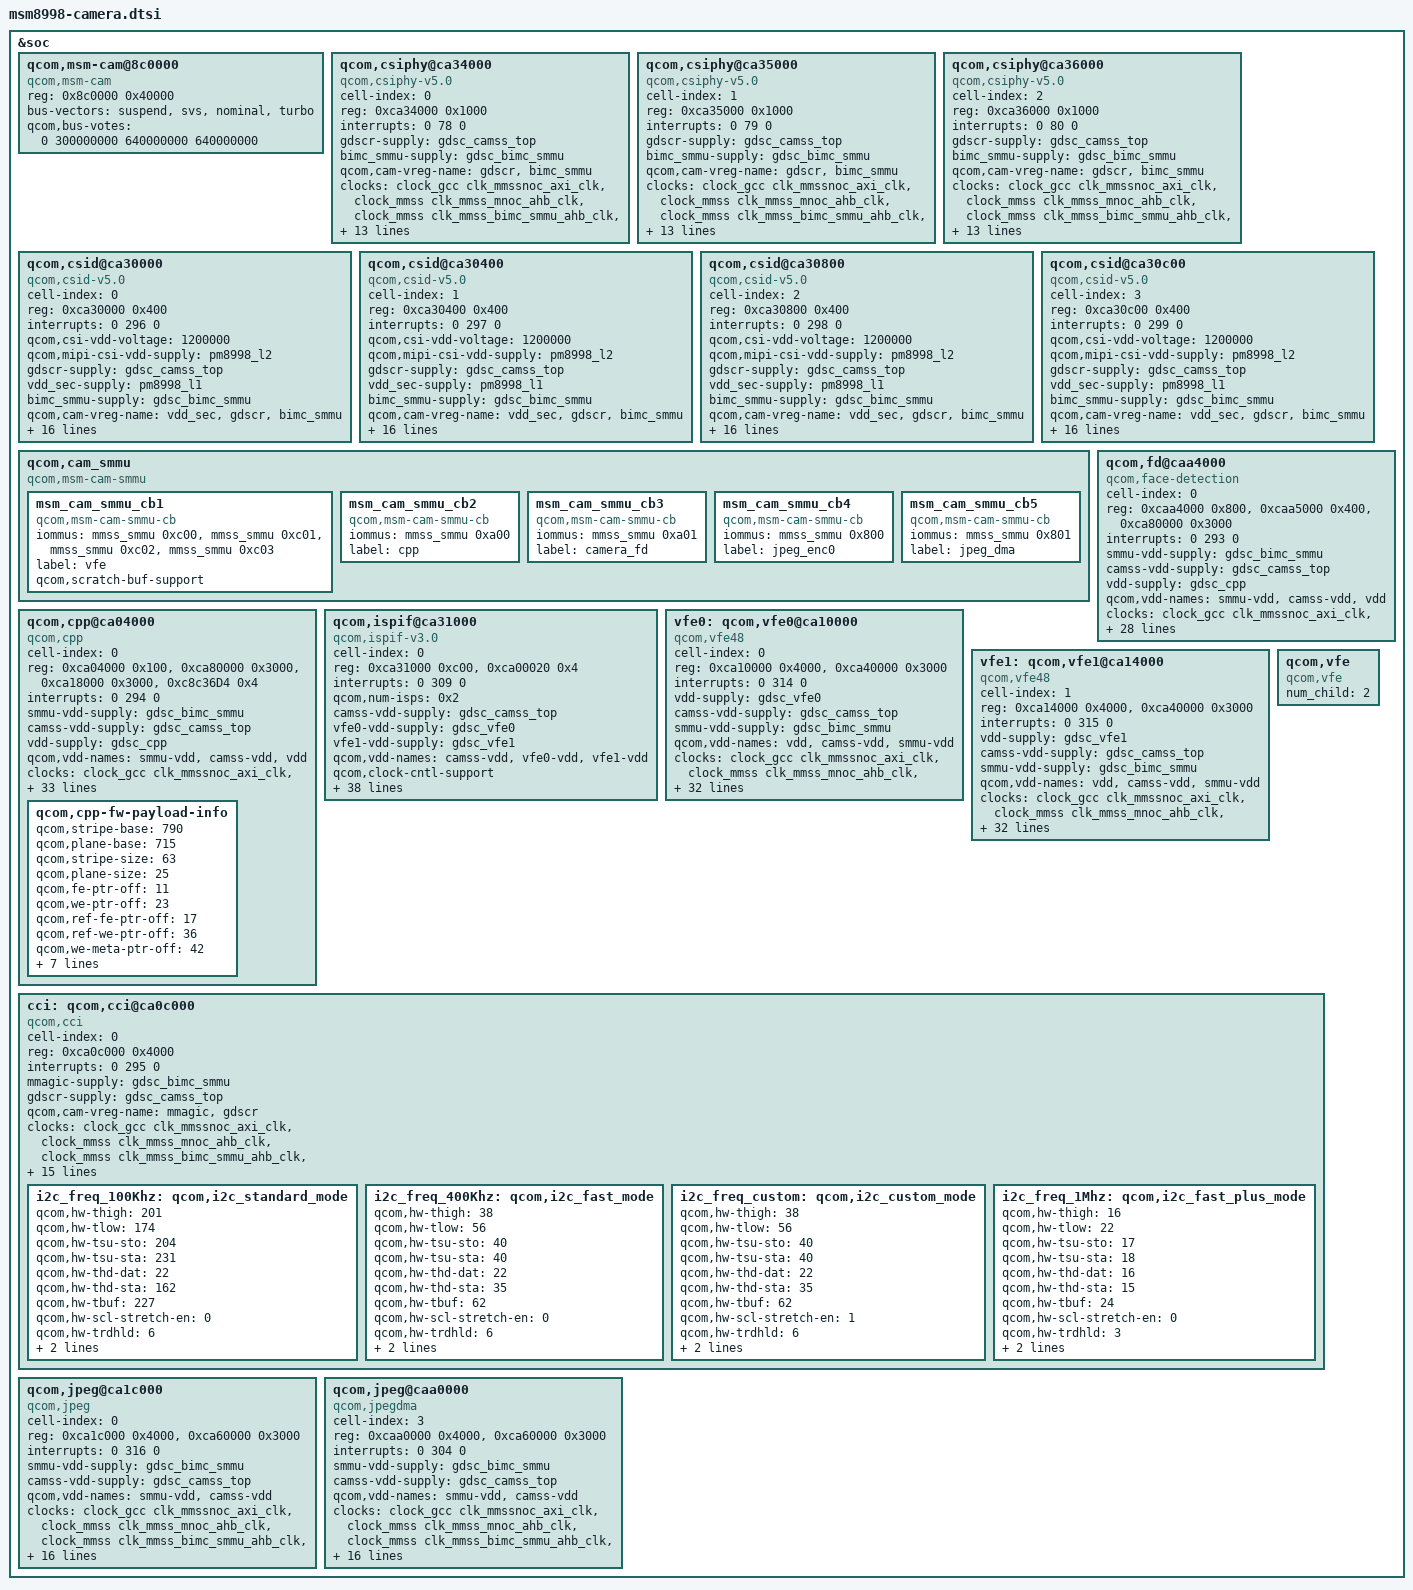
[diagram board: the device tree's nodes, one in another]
/*
 * Copyright (c) 2015-2017, The Linux Foundation. All rights reserved.
 *
 * This program is free software; you can redistribute it and/or modify
 * it under the terms of the GNU General Public License version 2 and
 * only version 2 as published by the Free Software Foundation.
 *
 * This program is distributed in the hope that it will be useful,
 * but WITHOUT ANY WARRANTY; without even the implied warranty of
 * MERCHANTABILITY or FITNESS FOR A PARTICULAR PURPOSE.  See the
 * GNU General Public License for more details.
 */

&soc {
	qcom,msm-cam@8c0000 {
		compatible = "qcom,msm-cam";
		reg = <0x8c0000 0x40000>;
		reg-names = "msm-cam";
		status = "ok";
		bus-vectors = "suspend", "svs", "nominal", "turbo";
		qcom,bus-votes = <0 300000000 640000000 640000000>;
	};

	qcom,csiphy@ca34000 {
		cell-index = <0>;
		compatible = "qcom,csiphy-v5.0", "qcom,csiphy";
		reg = <0xca34000 0x1000>;
		reg-names = "csiphy";
		interrupts = <0 78 0>;
		interrupt-names = "csiphy";
		gdscr-supply = <&gdsc_camss_top>;
		bimc_smmu-supply = <&gdsc_bimc_smmu>;
		qcom,cam-vreg-name = "gdscr", "bimc_smmu";
		clocks = <&clock_gcc clk_mmssnoc_axi_clk>,
			<&clock_mmss clk_mmss_mnoc_ahb_clk>,
			<&clock_mmss clk_mmss_bimc_smmu_ahb_clk>,
			<&clock_mmss clk_mmss_bimc_smmu_axi_clk>,
			<&clock_mmss clk_mmss_camss_ahb_clk>,
			<&clock_mmss clk_mmss_camss_top_ahb_clk>,
			<&clock_mmss clk_csi0_clk_src>,
			<&clock_mmss clk_mmss_camss_csi0_clk>,
			<&clock_mmss clk_mmss_camss_cphy_csid0_clk>,
			<&clock_mmss clk_csi0phytimer_clk_src>,
			<&clock_mmss clk_mmss_camss_csi0phytimer_clk>,
			<&clock_mmss clk_mmss_camss_ispif_ahb_clk>,
			<&clock_mmss clk_csiphy_clk_src>,
			<&clock_mmss clk_mmss_camss_csiphy0_clk>;
		clock-names = "mmssnoc_axi", "mnoc_ahb",
			"bmic_smmu_ahb", "bmic_smmu_axi",
			"camss_ahb_clk", "camss_top_ahb_clk",
			"csi_src_clk", "csi_clk", "cphy_csid_clk",
			"csiphy_timer_src_clk", "csiphy_timer_clk",
			"camss_ispif_ahb_clk", "csiphy_clk_src", "csiphy_clk";
		qcom,clock-rates = <0 0 0 0 0 0 274290000 0 0 200000000 0
			0 274290000 0>;
		status = "ok";
	};

	qcom,csiphy@ca35000 {
		cell-index = <1>;
		compatible = "qcom,csiphy-v5.0", "qcom,csiphy";
		reg = <0xca35000 0x1000>;
		reg-names = "csiphy";
		interrupts = <0 79 0>;
		interrupt-names = "csiphy";
		gdscr-supply = <&gdsc_camss_top>;
		bimc_smmu-supply = <&gdsc_bimc_smmu>;
		qcom,cam-vreg-name = "gdscr", "bimc_smmu";
		clocks = <&clock_gcc clk_mmssnoc_axi_clk>,
			<&clock_mmss clk_mmss_mnoc_ahb_clk>,
			<&clock_mmss clk_mmss_bimc_smmu_ahb_clk>,
			<&clock_mmss clk_mmss_bimc_smmu_axi_clk>,
			<&clock_mmss clk_mmss_camss_ahb_clk>,
			<&clock_mmss clk_mmss_camss_top_ahb_clk>,
			<&clock_mmss clk_csi1_clk_src>,
			<&clock_mmss clk_mmss_camss_csi1_clk>,
			<&clock_mmss clk_mmss_camss_cphy_csid1_clk>,
			<&clock_mmss clk_csi1phytimer_clk_src>,
			<&clock_mmss clk_mmss_camss_csi1phytimer_clk>,
			<&clock_mmss clk_mmss_camss_ispif_ahb_clk>,
			<&clock_mmss clk_csiphy_clk_src>,
			<&clock_mmss clk_mmss_camss_csiphy1_clk>;
		clock-names = "mmssnoc_axi", "mnoc_ahb",
			"bmic_smmu_ahb", "bmic_smmu_axi",
			"camss_ahb_clk", "camss_top_ahb_clk",
			"csi_src_clk", "csi_clk", "cphy_csid_clk",
			"csiphy_timer_src_clk", "csiphy_timer_clk",
			"camss_ispif_ahb_clk", "csiphy_clk_src", "csiphy_clk";
		qcom,clock-rates = <0 0 0 0 0 0 274290000 0 0 200000000 0
			0 274290000 0>;
		status = "ok";
	};

	qcom,csiphy@ca36000 {
		cell-index = <2>;
		compatible = "qcom,csiphy-v5.0", "qcom,csiphy";
		reg = <0xca36000 0x1000>;
		reg-names = "csiphy";
		interrupts = <0 80 0>;
		interrupt-names = "csiphy";
		gdscr-supply = <&gdsc_camss_top>;
		bimc_smmu-supply = <&gdsc_bimc_smmu>;
		qcom,cam-vreg-name = "gdscr", "bimc_smmu";
		clocks = <&clock_gcc clk_mmssnoc_axi_clk>,
			<&clock_mmss clk_mmss_mnoc_ahb_clk>,
			<&clock_mmss clk_mmss_bimc_smmu_ahb_clk>,
			<&clock_mmss clk_mmss_bimc_smmu_axi_clk>,
			<&clock_mmss clk_mmss_camss_ahb_clk>,
			<&clock_mmss clk_mmss_camss_top_ahb_clk>,
			<&clock_mmss clk_csi2_clk_src>,
			<&clock_mmss clk_mmss_camss_csi2_clk>,
			<&clock_mmss clk_mmss_camss_cphy_csid2_clk>,
			<&clock_mmss clk_csi2phytimer_clk_src>,
			<&clock_mmss clk_mmss_camss_csi2phytimer_clk>,
			<&clock_mmss clk_mmss_camss_ispif_ahb_clk>,
			<&clock_mmss clk_csiphy_clk_src>,
			<&clock_mmss clk_mmss_camss_csiphy2_clk>;
		clock-names = "mmssnoc_axi", "mnoc_ahb",
			"bmic_smmu_ahb", "bmic_smmu_axi",
			"camss_ahb_clk", "camss_top_ahb_clk",
			"csi_src_clk", "csi_clk", "cphy_csid_clk",
			"csiphy_timer_src_clk", "csiphy_timer_clk",
			"camss_ispif_ahb_clk", "csiphy_clk_src", "csiphy_clk";
		qcom,clock-rates = <0 0 0 0 0 0 274290000 0 0 200000000 0
			0 274290000 0>;
		status = "ok";
	};

	qcom,csid@ca30000  {
		cell-index = <0>;
		compatible = "qcom,csid-v5.0", "qcom,csid";
		reg = <0xca30000 0x400>;
		reg-names = "csid";
		interrupts = <0 296 0>;
		interrupt-names = "csid";
		qcom,csi-vdd-voltage = <1200000>;
		qcom,mipi-csi-vdd-supply = <&pm8998_l2>;
		gdscr-supply = <&gdsc_camss_top>;
		vdd_sec-supply = <&pm8998_l1>;
		bimc_smmu-supply = <&gdsc_bimc_smmu>;
		qcom,cam-vreg-name = "vdd_sec", "gdscr", "bimc_smmu";
		clocks = <&clock_gcc clk_mmssnoc_axi_clk>,
			<&clock_mmss clk_mmss_mnoc_ahb_clk>,
			<&clock_mmss clk_mmss_bimc_smmu_ahb_clk>,
			<&clock_mmss clk_mmss_bimc_smmu_axi_clk>,
			<&clock_mmss clk_mmss_camss_ahb_clk>,
			<&clock_mmss clk_mmss_camss_top_ahb_clk>,
			<&clock_mmss clk_mmss_camss_ispif_ahb_clk>,
			<&clock_mmss clk_csi0_clk_src>,
			<&clock_mmss clk_csiphy_clk_src>,
			<&clock_mmss clk_mmss_camss_csi0_clk>,
			<&clock_mmss clk_mmss_camss_csi0_ahb_clk>,
			<&clock_mmss clk_mmss_camss_csi0rdi_clk>,
			<&clock_mmss clk_mmss_camss_csi0pix_clk>,
			<&clock_mmss clk_mmss_camss_cphy_csid0_clk>;
		clock-names = "mmssnoc_axi", "mnoc_ahb",
			"bmic_smmu_ahb", "bmic_smmu_axi",
			"camss_ahb_clk", "camss_top_ahb_clk",
			"ispif_ahb_clk", "csi_src_clk", "csiphy_clk_src",
			"csi_clk", "csi_ahb_clk", "csi_rdi_clk",
			"csi_pix_clk", "cphy_csid_clk";
		qcom,clock-rates = <0 0 0 0 0 0 0 274290000 274290000
			0 0 0 0 0>;
		status = "ok";
	};

	qcom,csid@ca30400 {
		cell-index = <1>;
		compatible = "qcom,csid-v5.0", "qcom,csid";
		reg = <0xca30400 0x400>;
		reg-names = "csid";
		interrupts = <0 297 0>;
		interrupt-names = "csid";
		qcom,csi-vdd-voltage = <1200000>;
		qcom,mipi-csi-vdd-supply = <&pm8998_l2>;
		gdscr-supply = <&gdsc_camss_top>;
		vdd_sec-supply = <&pm8998_l1>;
		bimc_smmu-supply = <&gdsc_bimc_smmu>;
		qcom,cam-vreg-name = "vdd_sec", "gdscr", "bimc_smmu";
		clocks = <&clock_gcc clk_mmssnoc_axi_clk>,
			<&clock_mmss clk_mmss_mnoc_ahb_clk>,
			<&clock_mmss clk_mmss_bimc_smmu_ahb_clk>,
			<&clock_mmss clk_mmss_bimc_smmu_axi_clk>,
			<&clock_mmss clk_mmss_camss_ahb_clk>,
			<&clock_mmss clk_mmss_camss_top_ahb_clk>,
			<&clock_mmss clk_mmss_camss_ispif_ahb_clk>,
			<&clock_mmss clk_csi1_clk_src>,
			<&clock_mmss clk_csiphy_clk_src>,
			<&clock_mmss clk_mmss_camss_csi1_clk>,
			<&clock_mmss clk_mmss_camss_csi1_ahb_clk>,
			<&clock_mmss clk_mmss_camss_csi1rdi_clk>,
			<&clock_mmss clk_mmss_camss_csi1pix_clk>,
			<&clock_mmss clk_mmss_camss_cphy_csid1_clk>;
		clock-names = "mmssnoc_axi", "mnoc_ahb",
			"bmic_smmu_ahb", "bmic_smmu_axi",
			"camss_ahb_clk", "camss_top_ahb_clk",
			"ispif_ahb_clk", "csi_src_clk", "csiphy_clk_src",
			"csi_clk", "csi_ahb_clk", "csi_rdi_clk",
			"csi_pix_clk", "cphy_csid_clk";
		qcom,clock-rates = <0 0 0 0 0 0 0 274290000 274290000
			 0 0 0 0 0>;
		status = "ok";
	};

	qcom,csid@ca30800 {
		cell-index = <2>;
		compatible = "qcom,csid-v5.0", "qcom,csid";
		reg = <0xca30800 0x400>;
		reg-names = "csid";
		interrupts = <0 298 0>;
		interrupt-names = "csid";
		qcom,csi-vdd-voltage = <1200000>;
		qcom,mipi-csi-vdd-supply = <&pm8998_l2>;
		gdscr-supply = <&gdsc_camss_top>;
		vdd_sec-supply = <&pm8998_l1>;
		bimc_smmu-supply = <&gdsc_bimc_smmu>;
		qcom,cam-vreg-name = "vdd_sec", "gdscr", "bimc_smmu";
		clocks = <&clock_gcc clk_mmssnoc_axi_clk>,
			<&clock_mmss clk_mmss_mnoc_ahb_clk>,
			<&clock_mmss clk_mmss_bimc_smmu_ahb_clk>,
			<&clock_mmss clk_mmss_bimc_smmu_axi_clk>,
			<&clock_mmss clk_mmss_camss_ahb_clk>,
			<&clock_mmss clk_mmss_camss_top_ahb_clk>,
			<&clock_mmss clk_mmss_camss_ispif_ahb_clk>,
			<&clock_mmss clk_csi2_clk_src>,
			<&clock_mmss clk_csiphy_clk_src>,
			<&clock_mmss clk_mmss_camss_csi2_clk>,
			<&clock_mmss clk_mmss_camss_csi2_ahb_clk>,
			<&clock_mmss clk_mmss_camss_csi2rdi_clk>,
			<&clock_mmss clk_mmss_camss_csi2pix_clk>,
			<&clock_mmss clk_mmss_camss_cphy_csid2_clk>;
		clock-names = "mmssnoc_axi", "mnoc_ahb",
			"bmic_smmu_ahb", "bmic_smmu_axi",
			"camss_ahb_clk", "camss_top_ahb_clk",
			"ispif_ahb_clk", "csi_src_clk", "csiphy_clk_src",
			"csi_clk", "csi_ahb_clk", "csi_rdi_clk",
			"csi_pix_clk", "cphy_csid_clk";
		qcom,clock-rates = <0 0 0 0 0 0 0 274290000 274290000
			 0 0 0 0 0>;
		status = "ok";
	};

	qcom,csid@ca30c00 {
		cell-index = <3>;
		compatible = "qcom,csid-v5.0", "qcom,csid";
		reg = <0xca30c00 0x400>;
		reg-names = "csid";
		interrupts = <0 299 0>;
		interrupt-names = "csid";
		qcom,csi-vdd-voltage = <1200000>;
		qcom,mipi-csi-vdd-supply = <&pm8998_l2>;
		gdscr-supply = <&gdsc_camss_top>;
		vdd_sec-supply = <&pm8998_l1>;
		bimc_smmu-supply = <&gdsc_bimc_smmu>;
		qcom,cam-vreg-name = "vdd_sec", "gdscr", "bimc_smmu";
		clocks = <&clock_gcc clk_mmssnoc_axi_clk>,
			<&clock_mmss clk_mmss_mnoc_ahb_clk>,
			<&clock_mmss clk_mmss_bimc_smmu_ahb_clk>,
			<&clock_mmss clk_mmss_bimc_smmu_axi_clk>,
			<&clock_mmss clk_mmss_camss_ahb_clk>,
			<&clock_mmss clk_mmss_camss_top_ahb_clk>,
			<&clock_mmss clk_mmss_camss_ispif_ahb_clk>,
			<&clock_mmss clk_csi3_clk_src>,
			<&clock_mmss clk_csiphy_clk_src>,
			<&clock_mmss clk_mmss_camss_csi3_clk>,
			<&clock_mmss clk_mmss_camss_csi3_ahb_clk>,
			<&clock_mmss clk_mmss_camss_csi3rdi_clk>,
			<&clock_mmss clk_mmss_camss_csi3pix_clk>,
			<&clock_mmss clk_mmss_camss_cphy_csid3_clk>;
		clock-names = "mmssnoc_axi", "mnoc_ahb",
			"bmic_smmu_ahb", "bmic_smmu_axi",
			"camss_ahb_clk", "camss_top_ahb_clk",
			"ispif_ahb_clk", "csi_src_clk", "csiphy_clk_src",
			"csi_clk", "csi_ahb_clk", "csi_rdi_clk",
			"csi_pix_clk", "cphy_csid_clk";
		qcom,clock-rates = <0 0 0 0 0 0 0 274290000 274290000
			 0 0 0 0 0>;
		status = "ok";
	};

	qcom,cam_smmu {
		compatible = "qcom,msm-cam-smmu";
		status = "ok";

		msm_cam_smmu_cb1 {
			compatible = "qcom,msm-cam-smmu-cb";
			iommus = <&mmss_smmu 0xc00>,
					<&mmss_smmu 0xc01>,
					<&mmss_smmu 0xc02>,
					<&mmss_smmu 0xc03>;
			label = "vfe";
			qcom,scratch-buf-support;
		};

		msm_cam_smmu_cb2 {
			compatible = "qcom,msm-cam-smmu-cb";
			iommus = <&mmss_smmu 0xa00>;
			label = "cpp";
		};

		msm_cam_smmu_cb3 {
			compatible = "qcom,msm-cam-smmu-cb";
			iommus = <&mmss_smmu 0xa01>;
			label = "camera_fd";
		};

		msm_cam_smmu_cb4 {
			compatible = "qcom,msm-cam-smmu-cb";
			iommus = <&mmss_smmu 0x800>;
			label = "jpeg_enc0";
		};

		msm_cam_smmu_cb5 {
			compatible = "qcom,msm-cam-smmu-cb";
			iommus = <&mmss_smmu 0x801>;
			label = "jpeg_dma";
		};
	};

	qcom,fd@caa4000 {
		cell-index = <0>;
		compatible = "qcom,face-detection";
		reg = <0xcaa4000 0x800>,
			<0xcaa5000 0x400>,
			<0xca80000 0x3000>;
		reg-names = "fd_core", "fd_misc", "fd_vbif";
		interrupts = <0 293 0>;
		interrupt-names = "fd";
		smmu-vdd-supply = <&gdsc_bimc_smmu>;
		camss-vdd-supply = <&gdsc_camss_top>;
		vdd-supply = <&gdsc_cpp>;
		qcom,vdd-names = "smmu-vdd", "camss-vdd", "vdd";
		clocks = <&clock_gcc clk_mmssnoc_axi_clk>,
			<&clock_mmss clk_mmss_mnoc_ahb_clk>,
			<&clock_mmss clk_mmss_bimc_smmu_ahb_clk>,
			<&clock_mmss clk_mmss_bimc_smmu_axi_clk>,
			<&clock_mmss clk_mmss_camss_ahb_clk>,
			<&clock_mmss clk_mmss_camss_top_ahb_clk>,
			<&clock_mmss clk_mmss_fd_core_clk>,
			<&clock_mmss clk_mmss_fd_core_uar_clk>,
			<&clock_mmss clk_mmss_fd_ahb_clk>,
			<&clock_mmss clk_mmss_camss_cpp_axi_clk>,
			<&clock_mmss clk_mmss_camss_cpp_vbif_ahb_clk>;
		clock-names = "mmssnoc_axi",
			"mmss_mnoc_ahb_clk",
			"mmss_bimc_smmu_ahb_clk",
			"mmss_bimc_smmu_axi_clk",
			"mmss_camss_ahb_clk",
			"mmss_camss_top_ahb_clk",
			"mmss_fd_core_clk",
			"mmss_fd_core_uar_clk",
			"mmss_fd_ahb_clk",
			"mmss_camss_cpp_axi_clk",
			"mmss_camss_cpp_vbif_ahb_clk";
		qcom,clock-rates =
			<0 0 0 0 0 0 404000000 0 0 0 0>,
			<0 0 0 0 0 0 100000000 0 0 0 0>,
			<0 0 0 0 0 0 404000000 0 0 0 0>,
			<0 0 0 0 0 0 404000000 0 0 0 0>;
		qcom,msm-bus,name = "msm_camera_fd";
		qcom,msm-bus,num-cases = <4>;
		qcom,msm-bus,num-paths = <1>;
		qcom,msm-bus,vectors-KBps = <106 512 0 0>,
			<106 512 1625 0>,
			<106 512 2995 0>,
			<106 512 7200 0>;
		qcom,fd-vbif-reg-settings = <0x20 0x10000000 0x30000000>,
			<0x24 0x10000000 0x30000000>,
			<0x28 0x10000000 0x30000000>,
			<0x2c 0x10000000 0x30000000>;
		qcom,fd-misc-reg-settings = <0x20 0x2 0x3>,
			<0x24 0x2 0x3>;
		status = "ok";
	};

	qcom,cpp@ca04000 {
		cell-index = <0>;
		compatible = "qcom,cpp";
		reg = <0xca04000 0x100>,
			<0xca80000 0x3000>,
			<0xca18000 0x3000>,
			<0xc8c36D4 0x4>;
		reg-names = "cpp", "cpp_vbif", "cpp_hw", "camss_cpp";
		interrupts = <0 294 0>;
		interrupt-names = "cpp";
		smmu-vdd-supply = <&gdsc_bimc_smmu>;
		camss-vdd-supply = <&gdsc_camss_top>;
		vdd-supply = <&gdsc_cpp>;
		qcom,vdd-names = "smmu-vdd", "camss-vdd", "vdd";
		clocks = <&clock_gcc clk_mmssnoc_axi_clk>,
			<&clock_mmss clk_mmss_mnoc_ahb_clk>,
			<&clock_mmss clk_mmss_camss_ahb_clk>,
			<&clock_mmss clk_mmss_camss_top_ahb_clk>,
			<&clock_mmss clk_cpp_clk_src>,
			<&clock_mmss clk_mmss_camss_cpp_clk>,
			<&clock_mmss clk_mmss_camss_cpp_ahb_clk>,
			<&clock_mmss clk_mmss_camss_cpp_axi_clk>,
			<&clock_mmss clk_mmss_camss_micro_ahb_clk>,
			<&clock_mmss clk_mmss_bimc_smmu_axi_clk>,
			<&clock_mmss clk_mmss_camss_cpp_vbif_ahb_clk>;
		clock-names = "mmssnoc_axi_clk",
			"mnoc_ahb_clk",
			"camss_ahb_clk", "camss_top_ahb_clk",
			"cpp_src_clk",
			"cpp_core_clk", "camss_cpp_ahb_clk",
			"camss_cpp_axi_clk", "micro_iface_clk",
			"mmss_smmu_axi_clk", "cpp_vbif_ahb_clk";
		qcom,clock-rates = <0 0 0 0 200000000 200000000 0 0 0 0 0>;
		qcom,min-clock-rate = <200000000>;
		qcom,bus-master = <1>;
		qcom,vbif-qos-setting = <0x550 0x33333333>,
			<0x554 0x03333333>,
			<0x558 0x33333333>,
			<0x55c 0x03333333>,
			<0x560 0x33333333>,
			<0x564 0x03333333>,
			<0x568 0x33333333>,
			<0x56c 0x03333333>,
			<0x570 0x33333333>,
			<0x574 0x03333333>,
			<0x578 0x33333333>,
			<0x57c 0x03333333>,
			<0x580 0x33333333>,
			<0x584 0x03333333>,
			<0x588 0x33333333>,
			<0x58c 0x03333333>;
		status = "ok";
		qcom,msm-bus,name = "msm_camera_cpp";
		qcom,msm-bus,num-cases = <2>;
		qcom,msm-bus,num-paths = <1>;
		qcom,msm-bus,vectors-KBps =
			<106 512 0 0>,
			<106 512 0 0>;
		qcom,msm-bus-vector-dyn-vote;
		resets = <&clock_mmss CAMSS_MICRO_BCR>;
		reset-names = "micro_iface_reset";
		qcom,src-clock-rates = <100000000 200000000 576000000
			600000000>;
		qcom,micro-reset;
		qcom,cpp-fw-payload-info {
			qcom,stripe-base = <790>;
			qcom,plane-base = <715>;
			qcom,stripe-size = <63>;
			qcom,plane-size = <25>;
			qcom,fe-ptr-off = <11>;
			qcom,we-ptr-off = <23>;
			qcom,ref-fe-ptr-off = <17>;
			qcom,ref-we-ptr-off = <36>;
			qcom,we-meta-ptr-off = <42>;
			qcom,fe-mmu-pf-ptr-off = <7>;
			qcom,ref-fe-mmu-pf-ptr-off = <10>;
			qcom,we-mmu-pf-ptr-off = <13>;
			qcom,dup-we-mmu-pf-ptr-off = <18>;
			qcom,ref-we-mmu-pf-ptr-off = <23>;
			qcom,set-group-buffer-len = <135>;
			qcom,dup-frame-indicator-off = <70>;
		};
	};

	qcom,ispif@ca31000 {
		cell-index = <0>;
		compatible = "qcom,ispif-v3.0", "qcom,ispif";
		reg = <0xca31000 0xc00>,
			<0xca00020 0x4>;
		reg-names = "ispif", "csi_clk_mux";
		interrupts = <0 309 0>;
		interrupt-names = "ispif";
		qcom,num-isps = <0x2>;
		camss-vdd-supply = <&gdsc_camss_top>;
		vfe0-vdd-supply = <&gdsc_vfe0>;
		vfe1-vdd-supply = <&gdsc_vfe1>;
		qcom,vdd-names = "camss-vdd", "vfe0-vdd",
				"vfe1-vdd";
		qcom,clock-cntl-support;
		clocks = <&clock_gcc clk_mmssnoc_axi_clk>,
			<&clock_mmss clk_mmss_mnoc_ahb_clk>,
			<&clock_mmss clk_mmss_camss_ahb_clk>,
			<&clock_mmss clk_mmss_camss_top_ahb_clk>,
			<&clock_mmss clk_mmss_camss_ispif_ahb_clk>,
			<&clock_mmss clk_csi0_clk_src>,
			<&clock_mmss clk_csi1_clk_src>,
			<&clock_mmss clk_csi2_clk_src>,
			<&clock_mmss clk_csi3_clk_src>,
			<&clock_mmss clk_mmss_camss_csi0rdi_clk>,
			<&clock_mmss clk_mmss_camss_csi1rdi_clk>,
			<&clock_mmss clk_mmss_camss_csi2rdi_clk>,
			<&clock_mmss clk_mmss_camss_csi3rdi_clk>,
			<&clock_mmss clk_mmss_camss_csi0pix_clk>,
			<&clock_mmss clk_mmss_camss_csi1pix_clk>,
			<&clock_mmss clk_mmss_camss_csi2pix_clk>,
			<&clock_mmss clk_mmss_camss_csi3pix_clk>,
			<&clock_mmss clk_mmss_camss_csi0_clk>,
			<&clock_mmss clk_mmss_camss_csi1_clk>,
			<&clock_mmss clk_mmss_camss_csi2_clk>,
			<&clock_mmss clk_mmss_camss_csi3_clk>,
			<&clock_mmss clk_vfe0_clk_src>,
			<&clock_mmss clk_mmss_camss_vfe0_clk>,
			<&clock_mmss clk_mmss_camss_csi_vfe0_clk>,
			<&clock_mmss clk_vfe1_clk_src>,
			<&clock_mmss clk_mmss_camss_vfe1_clk>,
			<&clock_mmss clk_mmss_camss_csi_vfe1_clk>;
		clock-names = "mmssnoc_axi", "mnoc_ahb_clk",
			"camss_ahb_clk",
			"camss_top_ahb_clk", "ispif_ahb_clk",
			"csi0_src_clk", "csi1_src_clk",
			"csi2_src_clk", "csi3_src_clk",
			"csi0_rdi_clk", "csi1_rdi_clk",
			"csi2_rdi_clk", "csi3_rdi_clk",
			"csi0_pix_clk", "csi1_pix_clk",
			"csi2_pix_clk", "csi3_pix_clk",
			"camss_csi0_clk", "camss_csi1_clk",
			"camss_csi2_clk", "camss_csi3_clk",
			"vfe0_clk_src",
			"camss_vfe_vfe0_clk",
			"camss_csi_vfe0_clk",
			"vfe1_clk_src",
			"camss_vfe_vfe1_clk",
			"camss_csi_vfe1_clk";
		qcom,clock-rates = <0 0 0 0 0
			0 0 0 0
			0 0 0 0
			0 0 0 0
			0 0 0 0
			0 0 0
			0 0 0>;
		qcom,clock-control = "INIT_RATE", "NO_SET_RATE",
			"NO_SET_RATE", "NO_SET_RATE",
			"NO_SET_RATE",
			"INIT_RATE", "INIT_RATE",
			"INIT_RATE", "INIT_RATE",
			"NO_SET_RATE", "NO_SET_RATE",
			"NO_SET_RATE", "NO_SET_RATE",
			"NO_SET_RATE", "NO_SET_RATE",
			"NO_SET_RATE", "NO_SET_RATE",
			"NO_SET_RATE", "NO_SET_RATE",
			"NO_SET_RATE", "NO_SET_RATE",
			"INIT_RATE",
			"NO_SET_RATE", "NO_SET_RATE",
			"INIT_RATE",
			"NO_SET_RATE", "NO_SET_RATE";
		status = "ok";
	};

	vfe0: qcom,vfe0@ca10000 {
		cell-index = <0>;
		compatible = "qcom,vfe48";
		reg = <0xca10000 0x4000>,
			<0xca40000 0x3000>;
		reg-names = "vfe", "vfe_vbif";
		interrupts = <0 314 0>;
		interrupt-names = "vfe";
		vdd-supply = <&gdsc_vfe0>;
		camss-vdd-supply = <&gdsc_camss_top>;
		smmu-vdd-supply = <&gdsc_bimc_smmu>;
		qcom,vdd-names = "vdd", "camss-vdd", "smmu-vdd";
		clocks = <&clock_gcc clk_mmssnoc_axi_clk>,
			<&clock_mmss clk_mmss_mnoc_ahb_clk>,
			<&clock_mmss clk_mmss_bimc_smmu_ahb_clk>,
			<&clock_mmss clk_mmss_bimc_smmu_axi_clk>,
			<&clock_mmss clk_mmss_camss_ahb_clk>,
			<&clock_mmss clk_mmss_camss_top_ahb_clk>,
			<&clock_mmss clk_vfe0_clk_src>,
			<&clock_mmss clk_mmss_camss_vfe0_clk>,
			<&clock_mmss clk_mmss_camss_vfe0_stream_clk>,
			<&clock_mmss clk_mmss_camss_vfe0_ahb_clk>,
			<&clock_mmss clk_mmss_camss_vfe_vbif_ahb_clk>,
			<&clock_mmss clk_mmss_camss_vfe_vbif_axi_clk>,
			<&clock_mmss clk_mmss_camss_csi_vfe0_clk>;
		clock-names = "mmssnoc_axi", "mnoc_ahb_clk",
			"bimc_smmu_ahb_clk", "bimc_smmu_axi_clk",
			"camss_ahb_clk", "camss_top_ahb_clk", "vfe_clk_src",
			"camss_vfe_clk", "camss_vfe_stream_clk",
			"camss_vfe_ahb_clk", "camss_vfe_vbif_ahb_clk",
			"camss_vfe_vbif_axi_clk",
			"camss_csi_vfe_clk";
		qcom,clock-rates = <0 0 0 0 0 0 480000000 0 0 0 0 0 0
					0 0 0 0 0 0 576000000 0 0 0 0 0 0
					0 0 0 0 0 0 600000000 0 0 0 0 0 0>;
		status = "ok";
		qos-entries = <8>;
		qos-regs = <0x404 0x408 0x40c 0x410 0x414 0x418
			0x41c 0x420>;
		qos-settings = <0xaaa9aaa9
			0xaaa9aaa9
			0xaaa9aaa9
			0xaaa9aaa9
			0xaaa9aaa9
			0xaaa9aaa9
			0xaaa9aaa9
			0xaaa9aaa9>;
		vbif-entries = <1>;
		vbif-regs = <0x124>;
		vbif-settings = <0x3>;
		ds-entries = <17>;
		ds-regs = <0x424 0x428 0x42c 0x430 0x434
			0x438 0x43c 0x440 0x444 0x448 0x44c
			0x450 0x454 0x458 0x45c 0x460 0x464>;
		ds-settings = <0xcccc0011
			0xcccc0011
			0xcccc0011
			0xcccc0011
			0xcccc0011
			0xcccc0011
			0xcccc0011
			0xcccc0011
			0xcccc0011
			0xcccc0011
			0xcccc0011
			0xcccc0011
			0xcccc0011
			0xcccc0011
			0xcccc0011
			0xcccc0011
			0x40000103>;
		qcom,msm-bus,name = "msm_camera_vfe";
		qcom,msm-bus,num-cases = <2>;
		qcom,msm-bus,num-paths = <1>;
		qcom,msm-bus,vectors-KBps =
			<29 512 0 0>,
			<29 512 100000000 100000000>;
		qcom,msm-bus-vector-dyn-vote;
	};

	vfe1: qcom,vfe1@ca14000 {
		cell-index = <1>;
		compatible = "qcom,vfe48";
		reg = <0xca14000 0x4000>,
			<0xca40000 0x3000>;
		reg-names = "vfe", "vfe_vbif";
		interrupts = <0 315 0>;
		interrupt-names = "vfe";
		vdd-supply = <&gdsc_vfe1>;
		camss-vdd-supply = <&gdsc_camss_top>;
		smmu-vdd-supply = <&gdsc_bimc_smmu>;
		qcom,vdd-names = "vdd", "camss-vdd", "smmu-vdd";
		clocks = <&clock_gcc clk_mmssnoc_axi_clk>,
			<&clock_mmss clk_mmss_mnoc_ahb_clk>,
			<&clock_mmss clk_mmss_bimc_smmu_ahb_clk>,
			<&clock_mmss clk_mmss_bimc_smmu_axi_clk>,
			<&clock_mmss clk_mmss_camss_ahb_clk>,
			<&clock_mmss clk_mmss_camss_top_ahb_clk>,
			<&clock_mmss clk_vfe1_clk_src>,
			<&clock_mmss clk_mmss_camss_vfe1_clk>,
			<&clock_mmss clk_mmss_camss_vfe1_stream_clk>,
			<&clock_mmss clk_mmss_camss_vfe1_ahb_clk>,
			<&clock_mmss clk_mmss_camss_vfe_vbif_ahb_clk>,
			<&clock_mmss clk_mmss_camss_vfe_vbif_axi_clk>,
			<&clock_mmss clk_mmss_camss_csi_vfe1_clk>;
		clock-names = "mmssnoc_axi", "mnoc_ahb_clk",
			"bimc_smmu_ahb_clk", "bimc_smmu_axi_clk",
			"camss_ahb_clk", "camss_top_ahb_clk", "vfe_clk_src",
			"camss_vfe_clk", "camss_vfe_stream_clk",
			"camss_vfe_ahb_clk", "camss_vfe_vbif_ahb_clk",
			"camss_vfe_vbif_axi_clk",
			"camss_csi_vfe_clk";
		qcom,clock-rates = <0 0 0 0 0 0 480000000 0 0 0 0 0 0
					0 0 0 0 0 0 576000000 0 0 0 0 0 0
					0 0 0 0 0 0 600000000 0 0 0 0 0 0>;
		status = "ok";
		qos-entries = <8>;
		qos-regs = <0x404 0x408 0x40c 0x410 0x414 0x418
			0x41c 0x420>;
		qos-settings = <0xaaa9aaa9
			0xaaa9aaa9
			0xaaa9aaa9
			0xaaa9aaa9
			0xaaa9aaa9
			0xaaa9aaa9
			0xaaa9aaa9
			0xaaa9aaa9>;
		vbif-entries = <1>;
		vbif-regs = <0x124>;
		vbif-settings = <0x3>;
		ds-entries = <17>;
		ds-regs = <0x424 0x428 0x42c 0x430 0x434
			0x438 0x43c 0x440 0x444 0x448 0x44c
			0x450 0x454 0x458 0x45c 0x460 0x464>;
		ds-settings = <0xcccc0011
			0xcccc0011
			0xcccc0011
			0xcccc0011
			0xcccc0011
			0xcccc0011
			0xcccc0011
			0xcccc0011
			0xcccc0011
			0xcccc0011
			0xcccc0011
			0xcccc0011
			0xcccc0011
			0xcccc0011
			0xcccc0011
			0xcccc0011
			0x40000103>;
		qcom,msm-bus,name = "msm_camera_vfe";
		qcom,msm-bus,num-cases = <2>;
		qcom,msm-bus,num-paths = <1>;
		qcom,msm-bus,vectors-KBps =
			<29 512 0 0>,
			<29 512 100000000 100000000>;
		qcom,msm-bus-vector-dyn-vote;
	};

	qcom,vfe {
		compatible = "qcom,vfe";
		num_child = <2>;
	};

	cci: qcom,cci@ca0c000 {
		cell-index = <0>;
		compatible = "qcom,cci";
		reg = <0xca0c000 0x4000>;
		#address-cells = <1>;
		#size-cells = <0>;
		reg-names = "cci";
		interrupts = <0 295 0>;
		interrupt-names = "cci";
		status = "ok";
		mmagic-supply = <&gdsc_bimc_smmu>;
		gdscr-supply = <&gdsc_camss_top>;
		qcom,cam-vreg-name = "mmagic", "gdscr";
		clocks = <&clock_gcc clk_mmssnoc_axi_clk>,
			<&clock_mmss clk_mmss_mnoc_ahb_clk>,
			<&clock_mmss clk_mmss_bimc_smmu_ahb_clk>,
			<&clock_mmss clk_mmss_bimc_smmu_axi_clk>,
			<&clock_mmss clk_mmss_camss_ahb_clk>,
			<&clock_mmss clk_mmss_camss_top_ahb_clk>,
			<&clock_mmss clk_cci_clk_src>,
			<&clock_mmss clk_mmss_camss_cci_ahb_clk>,
			<&clock_mmss clk_mmss_camss_cci_clk>;
		clock-names = "mmssnoc_axi", "mnoc_ahb", "smmu_ahb", "smmu_axi",
			"camss_ahb_clk", "camss_top_ahb_clk",
			"cci_src_clk", "cci_ahb_clk", "camss_cci_clk";
		qcom,clock-rates = <0 0 0 0 0 0 19200000 0 0>,
			<0 0 0 0 0 0 37500000 0 0>;
		pinctrl-names = "cci_default", "cci_suspend";
			pinctrl-0 = <&cci0_active &cci1_active>;
			pinctrl-1 = <&cci0_suspend &cci1_suspend>;
		gpios = <&tlmm 17 0>,
			<&tlmm 18 0>,
			<&tlmm 19 0>,
			<&tlmm 20 0>;
		qcom,gpio-tbl-num = <0 1 2 3>;
		qcom,gpio-tbl-flags = <1 1 1 1>;
		qcom,gpio-tbl-label = "CCI_I2C_DATA0",
				      "CCI_I2C_CLK0",
				      "CCI_I2C_DATA1",
				      "CCI_I2C_CLK1";
		i2c_freq_100Khz: qcom,i2c_standard_mode {
			status = "disabled";
		};
		i2c_freq_400Khz: qcom,i2c_fast_mode {
			status = "disabled";
		};
		i2c_freq_custom: qcom,i2c_custom_mode {
			status = "disabled";
		};
		i2c_freq_1Mhz: qcom,i2c_fast_plus_mode {
			status = "disabled";
		};
	};

	qcom,jpeg@ca1c000 {
		cell-index = <0>;
		compatible = "qcom,jpeg";
		reg = <0xca1c000 0x4000>,
			<0xca60000 0x3000>;
		reg-names = "jpeg_hw", "jpeg_vbif";
		interrupts = <0 316 0>;
		interrupt-names = "jpeg";
		smmu-vdd-supply = <&gdsc_bimc_smmu>;
		camss-vdd-supply = <&gdsc_camss_top>;
		qcom,vdd-names = "smmu-vdd", "camss-vdd";
		clock-names = "mmssnoc_axi",
			"mmss_mnoc_ahb_clk",
			"mmss_bimc_smmu_ahb_clk",
			"mmss_bimc_smmu_axi_clk",
			"mmss_camss_ahb_clk",
			"mmss_camss_top_ahb_clk",
			"core_clk",
			"mmss_camss_jpeg_ahb_clk",
			"mmss_camss_jpeg_axi_clk";
		clocks = <&clock_gcc clk_mmssnoc_axi_clk>,
			<&clock_mmss clk_mmss_mnoc_ahb_clk>,
			<&clock_mmss clk_mmss_bimc_smmu_ahb_clk>,
			<&clock_mmss clk_mmss_bimc_smmu_axi_clk>,
			<&clock_mmss clk_mmss_camss_ahb_clk>,
			<&clock_mmss clk_mmss_camss_top_ahb_clk>,
			<&clock_mmss clk_mmss_camss_jpeg0_vote_clk>,
			<&clock_mmss clk_mmss_camss_jpeg_ahb_clk>,
			<&clock_mmss clk_mmss_camss_jpeg_axi_clk>;
		qcom,clock-rates = <0 0 0 0 0 0 480000000 0 0>;
		qcom,vbif-reg-settings = <0x4 0x1>;
		qcom,prefetch-reg-settings = <0x30c 0x1111>,
			<0x318 0x31>,
			<0x324 0x31>,
			<0x330 0x31>,
			<0x33c 0x0>;
		qcom,msm-bus,name = "msm_camera_jpeg0";
		qcom,msm-bus,num-cases = <2>;
		qcom,msm-bus,num-paths = <1>;
		qcom,msm-bus,vectors-KBps = <62 512 0 0>,
			<62 512 1920000 2880000>;
		status = "ok";
	};

	qcom,jpeg@caa0000 {
		cell-index = <3>;
		compatible = "qcom,jpegdma";
		reg = <0xcaa0000 0x4000>,
			<0xca60000 0x3000>;
		reg-names = "jpeg_hw", "jpeg_vbif";
		interrupts = <0 304 0>;
		interrupt-names = "jpeg";
		smmu-vdd-supply = <&gdsc_bimc_smmu>;
		camss-vdd-supply = <&gdsc_camss_top>;
		qcom,vdd-names = "smmu-vdd", "camss-vdd";
		clock-names = "mmssnoc_axi",
			"mmss_mnoc_ahb_clk",
			"mmss_bimc_smmu_ahb_clk",
			"mmss_bimc_smmu_axi_clk",
			"mmss_camss_ahb_clk",
			"mmss_camss_top_ahb_clk",
			"core_clk",
			"mmss_camss_jpeg_ahb_clk",
			"mmss_camss_jpeg_axi_clk";
		clocks = <&clock_gcc clk_mmssnoc_axi_clk>,
			<&clock_mmss clk_mmss_mnoc_ahb_clk>,
			<&clock_mmss clk_mmss_bimc_smmu_ahb_clk>,
			<&clock_mmss clk_mmss_bimc_smmu_axi_clk>,
			<&clock_mmss clk_mmss_camss_ahb_clk>,
			<&clock_mmss clk_mmss_camss_top_ahb_clk>,
			<&clock_mmss clk_mmss_camss_jpeg0_dma_vote_clk>,
			<&clock_mmss clk_mmss_camss_jpeg_ahb_clk>,
			<&clock_mmss clk_mmss_camss_jpeg_axi_clk>;
		qcom,clock-rates = <0 0 0 0 0 0 480000000 0 0>;
		qcom,vbif-reg-settings = <0x4 0x1>;
		qcom,prefetch-reg-settings = <0x18c 0x11>,
			<0x1a0 0x31>,
			<0x1b0 0x31>;
		qcom,msm-bus,name = "msm_camera_jpeg_dma";
		qcom,msm-bus,num-cases = <2>;
		qcom,msm-bus,num-paths = <1>;
		qcom,msm-bus,vectors-KBps = <62 512 0 0>,
			<62 512 1920000 2880000>;
		qcom,max-ds-factor = <128>;
		status = "ok";
	};
};

&i2c_freq_100Khz {
	qcom,hw-thigh = <201>;
	qcom,hw-tlow = <174>;
	qcom,hw-tsu-sto = <204>;
	qcom,hw-tsu-sta = <231>;
	qcom,hw-thd-dat = <22>;
	qcom,hw-thd-sta = <162>;
	qcom,hw-tbuf = <227>;
	qcom,hw-scl-stretch-en = <0>;
	qcom,hw-trdhld = <6>;
	qcom,hw-tsp = <3>;
	qcom,cci-clk-src = <37500000>;
	status = "ok";
};

&i2c_freq_400Khz {
	qcom,hw-thigh = <38>;
	qcom,hw-tlow = <56>;
	qcom,hw-tsu-sto = <40>;
	qcom,hw-tsu-sta = <40>;
	qcom,hw-thd-dat = <22>;
	qcom,hw-thd-sta = <35>;
	qcom,hw-tbuf = <62>;
	qcom,hw-scl-stretch-en = <0>;
	qcom,hw-trdhld = <6>;
	qcom,hw-tsp = <3>;
	qcom,cci-clk-src = <37500000>;
	status = "ok";
};

&i2c_freq_custom {
	qcom,hw-thigh = <38>;
	qcom,hw-tlow = <56>;
	qcom,hw-tsu-sto = <40>;
	qcom,hw-tsu-sta = <40>;
	qcom,hw-thd-dat = <22>;
	qcom,hw-thd-sta = <35>;
	qcom,hw-tbuf = <62>;
	qcom,hw-scl-stretch-en = <1>;
	qcom,hw-trdhld = <6>;
	qcom,hw-tsp = <3>;
	qcom,cci-clk-src = <37500000>;
	status = "ok";
};

&i2c_freq_1Mhz {
	qcom,hw-thigh = <16>;
	qcom,hw-tlow = <22>;
	qcom,hw-tsu-sto = <17>;
	qcom,hw-tsu-sta = <18>;
	qcom,hw-thd-dat = <16>;
	qcom,hw-thd-sta = <15>;
	qcom,hw-tbuf = <24>;
	qcom,hw-scl-stretch-en = <0>;
	qcom,hw-trdhld = <3>;
	qcom,hw-tsp = <3>;
	qcom,cci-clk-src = <37500000>;
	status = "ok";
};
